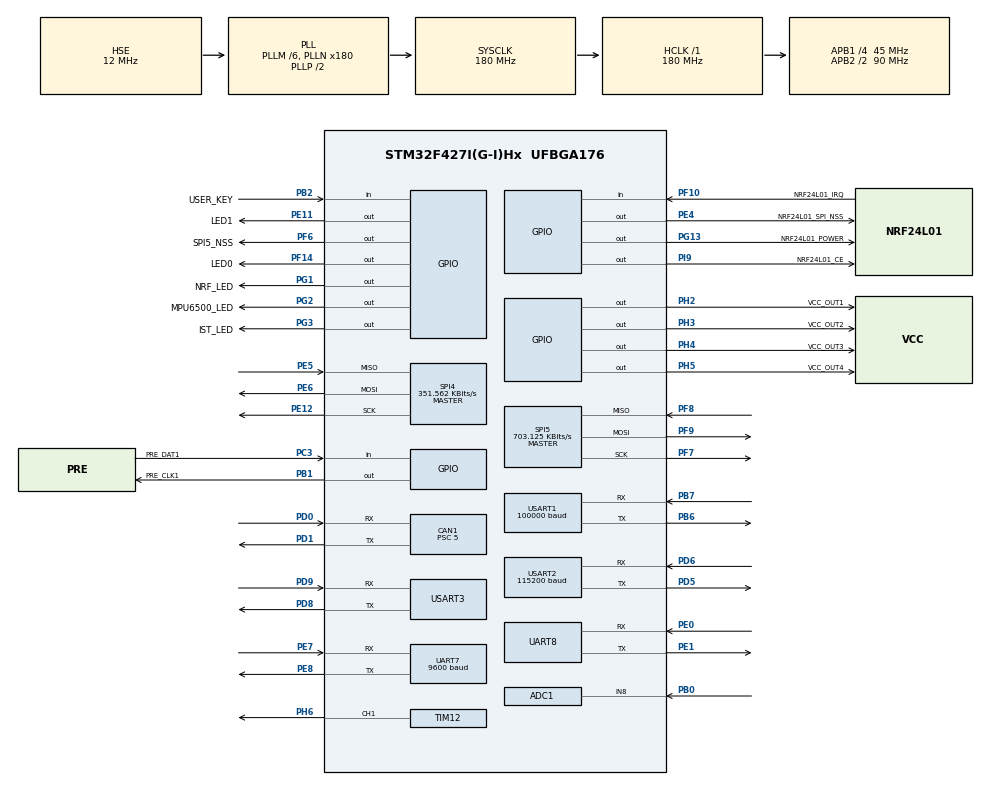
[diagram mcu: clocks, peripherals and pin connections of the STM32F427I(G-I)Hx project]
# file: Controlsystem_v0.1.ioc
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ADC1.Channel-0\#ChannelRegularConversion=ADC_CHANNEL_8
ADC1.NbrOfConversionFlag=1
ADC1.Rank-0\#ChannelRegularConversion=1
ADC1.SamplingTime-0\#ChannelRegularConversion=ADC_SAMPLETIME_3CYCLES
ADC1.master=1
CAN1.ABOM=ENABLE
CAN1.AWUM=DISABLE
CAN1.BS1=CAN_BS1_3TQ
CAN1.BS2=CAN_BS2_5TQ
CAN1.CalculateBaudRate=1000000
CAN1.CalculateTimeBit=1000
CAN1.CalculateTimeQuantum=111.11111111111111
CAN1.NART=DISABLE
CAN1.Prescaler=5
Dma.Request0=USART1_RX
Dma.Request1=USART3_RX
Dma.Request2=USART3_TX
Dma.Request3=UART8_RX
Dma.Request4=UART8_TX
Dma.UART8_RX.3.Direction=DMA_PERIPH_TO_MEMORY
Dma.UART8_RX.3.FIFOMode=DMA_FIFOMODE_DISABLE
Dma.UART8_RX.3.Instance=DMA1_Stream6
Dma.UART8_RX.3.MemDataAlignment=DMA_MDATAALIGN_BYTE
Dma.UART8_RX.3.MemInc=DMA_MINC_ENABLE
Dma.UART8_RX.3.Mode=DMA_NORMAL
Dma.UART8_RX.3.PeriphDataAlignment=DMA_PDATAALIGN_BYTE
Dma.UART8_RX.3.PeriphInc=DMA_PINC_DISABLE
Dma.UART8_RX.3.Priority=DMA_PRIORITY_LOW
Dma.UART8_TX.4.Direction=DMA_MEMORY_TO_PERIPH
Dma.UART8_TX.4.FIFOMode=DMA_FIFOMODE_DISABLE
Dma.UART8_TX.4.Instance=DMA1_Stream0
Dma.UART8_TX.4.MemDataAlignment=DMA_MDATAALIGN_BYTE
Dma.UART8_TX.4.MemInc=DMA_MINC_ENABLE
Dma.UART8_TX.4.Mode=DMA_NORMAL
Dma.UART8_TX.4.PeriphDataAlignment=DMA_PDATAALIGN_BYTE
Dma.UART8_TX.4.PeriphInc=DMA_PINC_DISABLE
Dma.UART8_TX.4.Priority=DMA_PRIORITY_LOW
Dma.USART1_RX.0.Direction=DMA_PERIPH_TO_MEMORY
Dma.USART1_RX.0.FIFOMode=DMA_FIFOMODE_DISABLE
Dma.USART1_RX.0.Instance=DMA2_Stream2
Dma.USART1_RX.0.MemDataAlignment=DMA_MDATAALIGN_BYTE
Dma.USART1_RX.0.MemInc=DMA_MINC_ENABLE
Dma.USART1_RX.0.Mode=DMA_CIRCULAR
Dma.USART1_RX.0.PeriphDataAlignment=DMA_PDATAALIGN_BYTE
Dma.USART1_RX.0.PeriphInc=DMA_PINC_DISABLE
Dma.USART1_RX.0.Priority=DMA_PRIORITY_LOW
Dma.USART3_RX.1.Direction=DMA_PERIPH_TO_MEMORY
Dma.USART3_RX.1.FIFOMode=DMA_FIFOMODE_DISABLE
Dma.USART3_RX.1.Instance=DMA1_Stream1
Dma.USART3_RX.1.MemDataAlignment=DMA_MDATAALIGN_BYTE
Dma.USART3_RX.1.MemInc=DMA_MINC_ENABLE
Dma.USART3_RX.1.Mode=DMA_NORMAL
Dma.USART3_RX.1.PeriphDataAlignment=DMA_PDATAALIGN_BYTE
Dma.USART3_RX.1.PeriphInc=DMA_PINC_DISABLE
Dma.USART3_RX.1.Priority=DMA_PRIORITY_VERY_HIGH
Dma.USART3_TX.2.Direction=DMA_MEMORY_TO_PERIPH
Dma.USART3_TX.2.FIFOMode=DMA_FIFOMODE_DISABLE
Dma.USART3_TX.2.Instance=DMA1_Stream3
Dma.USART3_TX.2.MemDataAlignment=DMA_MDATAALIGN_BYTE
Dma.USART3_TX.2.MemInc=DMA_MINC_ENABLE
Dma.USART3_TX.2.Mode=DMA_NORMAL
Dma.USART3_TX.2.PeriphDataAlignment=DMA_PDATAALIGN_BYTE
Dma.USART3_TX.2.PeriphInc=DMA_PINC_DISABLE
Dma.USART3_TX.2.Priority=DMA_PRIORITY_HIGH
FREERTOS.INCLUDE_xTaskGetHandle=1
FREERTOS.Tasks01=defaultTask,-3,128,StartDefaultTask,Default,NULL,Dynamic,NULL,NULL;MotorTask,3,128,Motordrive_task,As weak,NULL,Dynamic,NULL,NULL;ARHSTask,2,512,arhs_task,As weak,NULL,Dynamic,NULL,NULL;GimbalTask,-2,256,gimbal_task,As weak,NULL,Dynamic,NULL,NULL;MeasureTask,1,128,measureTask,As weak,NULL,Dynamic,NULL,NULL;ComTask,0,256,comTask,As weak,NULL,Dynamic,NULL,NULL
FREERTOS.configENABLE_FPU=1
FREERTOS.configTOTAL_HEAP_SIZE=49152
FREERTOS.configUSE_APPLICATION_TASK_TAG=0
FREERTOS.configUSE_NEWLIB_REENTRANT=1
Mcu.Family=STM32F4
Mcu.Name=STM32F427I(G-I)Hx
Mcu.Package=UFBGA176
NVIC.CAN1_RX0_IRQn=true\:2\:0\:true\:false\:true\:false\:true\:true
NVIC.CAN1_TX_IRQn=true\:2\:0\:true\:false\:true\:false\:true\:true
NVIC.DMA1_Stream0_IRQn=true\:5\:0\:false\:false\:true\:true\:false\:true
NVIC.DMA1_Stream1_IRQn=true\:5\:0\:false\:false\:true\:true\:false\:true
NVIC.DMA1_Stream3_IRQn=true\:5\:0\:false\:false\:true\:true\:false\:true
NVIC.DMA1_Stream6_IRQn=true\:5\:0\:false\:false\:true\:true\:false\:true
NVIC.DMA2_Stream2_IRQn=true\:0\:0\:true\:false\:true\:false\:false\:true
NVIC.PriorityGroup=NVIC_PRIORITYGROUP_4
NVIC.TIM6_DAC_IRQn=true\:0\:0\:false\:false\:true\:false\:false\:true
NVIC.TimeBase=TIM6_DAC_IRQn
NVIC.TimeBaseIP=TIM6
NVIC.UART7_IRQn=true\:4\:0\:true\:false\:true\:false\:true\:true
NVIC.UART8_IRQn=true\:5\:0\:false\:false\:true\:true\:true\:true
NVIC.USART1_IRQn=true\:4\:0\:true\:false\:true\:false\:true\:true
NVIC.USART3_IRQn=true\:3\:0\:true\:false\:true\:false\:true\:true
PA13.Mode=Trace_Asynchronous_SW
PA13.Signal=SYS_JTMS-SWDIO
PA14.Mode=Trace_Asynchronous_SW
PA14.Signal=SYS_JTCK-SWCLK
PB0.Signal=ADCx_IN8
PB1.GPIO_Label=PRE_CLK1
PB1.GPIO_PuPd=GPIO_PULLUP
PB1.GPIO_Speed=GPIO_SPEED_FREQ_LOW
PB1.Signal=GPIO_Output
PB2/BOOT1.GPIO_Label=USER_KEY
PB2/BOOT1.GPIO_PuPd=GPIO_PULLUP
PB2/BOOT1.Signal=GPIO_Input
PB3.Mode=Trace_Asynchronous_SW
PB3.Signal=SYS_JTDO-SWO
PB6.Mode=Asynchronous
PB6.Signal=USART1_TX
PB7.Mode=Asynchronous
PB7.Signal=USART1_RX
PC14/OSC32_IN.Mode=LSE-External-Oscillator
PC14/OSC32_IN.Signal=RCC_OSC32_IN
PC15/OSC32_OUT.Mode=LSE-External-Oscillator
PC15/OSC32_OUT.Signal=RCC_OSC32_OUT
PC3.GPIO_Label=PRE_DAT1
PC3.GPIO_PuPd=GPIO_PULLUP
PC3.Signal=GPIO_Input
PD0.Mode=CAN_Activate
PD0.Signal=CAN1_RX
PD1.Mode=CAN_Activate
PD1.Signal=CAN1_TX
PD5.GPIO_PuPd=GPIO_NOPULL
PD5.Mode=Asynchronous
PD5.Signal=USART2_TX
PD6.Mode=Asynchronous
PD6.Signal=USART2_RX
PD8.Mode=Asynchronous
PD8.Signal=USART3_TX
PD9.Mode=Asynchronous
PD9.Signal=USART3_RX
PE0.Mode=Asynchronous
PE0.Signal=UART8_RX
PE1.Mode=Asynchronous
PE1.Signal=UART8_TX
PE11.GPIO_Label=LED1
PE11.GPIO_PuPd=GPIO_PULLUP
PE11.GPIO_Speed=GPIO_SPEED_FREQ_LOW
PE11.PinState=GPIO_PIN_RESET
PE11.Signal=GPIO_Output
PE12.GPIO_PuPd=GPIO_NOPULL
PE12.Mode=Full_Duplex_Master
PE12.Signal=SPI4_SCK
PE4.GPIO_Label=NRF24L01_SPI_NSS
PE4.GPIO_PuPd=GPIO_PULLUP
PE4.GPIO_Speed=GPIO_SPEED_FREQ_VERY_HIGH
PE4.PinState=GPIO_PIN_SET
PE4.Signal=GPIO_Output
PE5.GPIO_PuPd=GPIO_NOPULL
PE5.Mode=Full_Duplex_Master
PE5.Signal=SPI4_MISO
PE6.GPIO_PuPd=GPIO_NOPULL
PE6.Mode=Full_Duplex_Master
PE6.Signal=SPI4_MOSI
PE7.Mode=Asynchronous
PE7.Signal=UART7_RX
PE8.Mode=Asynchronous
PE8.Signal=UART7_TX
PF10.GPIO_Label=NRF24L01_IRQ
PF10.GPIO_PuPd=GPIO_NOPULL
PF10.Signal=GPIO_Input
PF14.GPIO_Label=LED0
PF14.GPIO_PuPd=GPIO_PULLUP
PF14.Signal=GPIO_Output
PF6.GPIO_Label=SPI5_NSS
PF6.GPIO_Speed=GPIO_SPEED_FREQ_MEDIUM
PF6.PinState=GPIO_PIN_SET
PF6.Signal=GPIO_Output
PF7.Mode=Full_Duplex_Master
PF7.Signal=SPI5_SCK
PF8.Mode=Full_Duplex_Master
PF8.Signal=SPI5_MISO
PF9.Mode=Full_Duplex_Master
PF9.Signal=SPI5_MOSI
PG1.GPIO_Label=NRF_LED
PG1.PinState=GPIO_PIN_SET
PG1.Signal=GPIO_Output
PG13.GPIO_Label=NRF24L01_POWER
PG13.Signal=GPIO_Output
PG2.GPIO_Label=MPU6500_LED
PG2.PinState=GPIO_PIN_RESET
PG2.Signal=GPIO_Output
PG3.GPIO_Label=IST_LED
PG3.PinState=GPIO_PIN_SET
PG3.Signal=GPIO_Output
PH0/OSC_IN.Mode=HSE-External-Oscillator
PH0/OSC_IN.Signal=RCC_OSC_IN
PH1/OSC_OUT.Mode=HSE-External-Oscillator
PH1/OSC_OUT.Signal=RCC_OSC_OUT
PH2.GPIO_Label=VCC_OUT1
PH2.Signal=GPIO_Output
PH3.GPIO_Label=VCC_OUT2
PH3.Signal=GPIO_Output
PH4.GPIO_Label=VCC_OUT3
PH4.Signal=GPIO_Output
PH5.GPIO_Label=VCC_OUT4
PH5.Signal=GPIO_Output
PH6.Signal=S_TIM12_CH1
PI9.GPIO_Label=NRF24L01_CE
PI9.GPIO_PuPd=GPIO_PULLUP
PI9.GPIO_Speed=GPIO_SPEED_FREQ_VERY_HIGH
PI9.Signal=GPIO_Output
ProjectManager.HeapSize=0x200
ProjectManager.StackSize=0x400
ProjectManager.TargetToolchain=STM32CubeIDE
RCC.48MHZClocksFreq_Value=90000000
RCC.AHBFreq_Value=180000000
RCC.APB1CLKDivider=RCC_HCLK_DIV4
RCC.APB1Freq_Value=45000000
RCC.APB1TimFreq_Value=90000000
RCC.APB2CLKDivider=RCC_HCLK_DIV2
RCC.APB2Freq_Value=90000000
RCC.APB2TimFreq_Value=180000000
RCC.CortexFreq_Value=180000000
RCC.HCLKFreq_Value=180000000
RCC.HSE_VALUE=12000000
RCC.HSI_VALUE=16000000
RCC.PLLM=6
RCC.PLLN=180
RCC.PLLSourceVirtual=RCC_PLLSOURCE_HSE
RCC.RCC_TIM_PRescaler_Selection=RCC_TIMPRES_DESACTIVATED
RCC.SYSCLKFreq_VALUE=180000000
RCC.SYSCLKSource=RCC_SYSCLKSOURCE_PLLCLK
RCC.VCOOutputFreq_Value=360000000
SH.ADCx_IN8.0=ADC1_IN8,IN8
SH.S_TIM12_CH1.0=TIM12_CH1,PWM Generation1 CH1
SPI4.BaudRatePrescaler=SPI_BAUDRATEPRESCALER_256
SPI4.CLKPhase=SPI_PHASE_1EDGE
SPI4.CLKPolarity=SPI_POLARITY_LOW
SPI4.CalculateBaudRate=351.562 KBits/s
SPI4.Direction=SPI_DIRECTION_2LINES
SPI4.Mode=SPI_MODE_MASTER
SPI4.VirtualType=VM_MASTER
SPI5.BaudRatePrescaler=SPI_BAUDRATEPRESCALER_128
SPI5.CLKPhase=SPI_PHASE_2EDGE
SPI5.CLKPolarity=SPI_POLARITY_HIGH
SPI5.CalculateBaudRate=703.125 KBits/s
SPI5.Direction=SPI_DIRECTION_2LINES
SPI5.Mode=SPI_MODE_MASTER
SPI5.VirtualType=VM_MASTER
TIM12.Channel-PWM\ Generation1\ CH1=TIM_CHANNEL_1
TIM12.Period=22499
TIM14.AutoReloadPreload=TIM_AUTORELOAD_PRELOAD_DISABLE
TIM14.ClockDivision=TIM_CLOCKDIVISION_DIV2
TIM14.Period=65535
TIM14.Prescaler=45
TIM3.Period=4999
UART7.BaudRate=9600
UART7.VirtualMode=Asynchronous
UART8.VirtualMode=Asynchronous
USART1.BaudRate=100000
USART1.Parity=PARITY_EVEN
USART1.VirtualMode=VM_ASYNC
USART2.BaudRate=115200
USART2.VirtualMode=VM_ASYNC
USART3.VirtualMode=VM_ASYNC
VP_FREERTOS_VS_CMSIS_V1.Mode=CMSIS_V1
VP_SYS_VS_tim6.Mode=TIM6
VP_TIM12_VS_ClockSourceINT.Mode=Internal
VP_TIM14_VS_ClockSourceINT.Mode=Enable_Timer
VP_TIM3_VS_ClockSourceINT.Mode=Internal
board=custom

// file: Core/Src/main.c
/* USER CODE BEGIN Header */
/**
  ******************************************************************************
  * @file           : main.c
  * @brief          : Main program body
  ******************************************************************************
  * @attention
  *
  * <h2><center>&copy; Copyright (c) 2020 STMicroelectronics.
  * All rights reserved.</center></h2>
  *
  * This software component is licensed by ST under BSD 3-Clause license,
  * the "License"; You may not use this file except in compliance with the
  * License. You may obtain a copy of the License at:
  *                        opensource.org/licenses/BSD-3-Clause
  *
  ******************************************************************************
  */
/* USER CODE END Header */
#include "main.h"
#include "FreeRTOS.h"
#include "cmsis_os.h"
#include "adc.h"
#include "can.h"
#include "dma.h"
#include "spi.h"
#include "tim.h"
#include "usart.h"
#include "gpio.h"

/* USER CODE BEGIN Includes */

//extern UART_HandleTypeDef huart7;

/* USER CODE END Includes */

/* USER CODE BEGIN PTD */
//extern CAN_HandleTypeDef hcan1;
extern TIM_HandleTypeDef htim12;
/* USER CODE END PTD */

void SystemClock_Config(void);
void MX_FREERTOS_Init(void);

int main(void)
{

  /* MCU Configuration--------------------------------------------------------*/

  /* Reset of all peripherals, Initializes the Flash interface and the Systick. */
  HAL_Init();

  /* Configure the system clock */
  SystemClock_Config();

  /* Initialize all configured peripherals */
  MX_GPIO_Init();
  MX_DMA_Init();
  MX_USART2_UART_Init();
  MX_USART1_UART_Init();
  MX_CAN1_Init();
  MX_SPI5_Init();
  MX_TIM3_Init();
  MX_UART7_Init();
  MX_USART3_UART_Init();
  MX_SPI4_Init();
  MX_ADC1_Init();
  MX_TIM14_Init();
  MX_TIM12_Init();
  MX_UART8_Init();
  /* USER CODE BEGIN 2 */
  //__HAL_UART_ENABLE_IT(&huart7, UART_IT_RXNE);
  HAL_TIM_Base_Start(&htim12);		//开启蜂鸣器定时器
  HAL_TIM_PWM_Start(&htim12, TIM_CHANNEL_1);	//开启蜂鸣器PWM波定时器

  /* USER CODE END 2 */

  /* Call init function for freertos objects (in freertos.c) */
  MX_FREERTOS_Init();
  /* Start scheduler */
  osKernelStart();

  /* We should never get here as control is now taken by the scheduler */
  /* Infinite loop */
  while (1)
  {

  }
}

void SystemClock_Config(void)
{
  RCC_OscInitTypeDef RCC_OscInitStruct = {0};
  RCC_ClkInitTypeDef RCC_ClkInitStruct = {0};

  /** Configure the main internal regulator output voltage
  */
  __HAL_RCC_PWR_CLK_ENABLE();
  __HAL_PWR_VOLTAGESCALING_CONFIG(PWR_REGULATOR_VOLTAGE_SCALE1);
  /** Initializes the RCC Oscillators according to the specified parameters
  * in the RCC_OscInitTypeDef structure.
  */
  RCC_OscInitStruct.OscillatorType = RCC_OSCILLATORTYPE_HSE;
  RCC_OscInitStruct.HSEState = RCC_HSE_ON;
  RCC_OscInitStruct.PLL.PLLState = RCC_PLL_ON;
  RCC_OscInitStruct.PLL.PLLSource = RCC_PLLSOURCE_HSE;
  RCC_OscInitStruct.PLL.PLLM = 6;
  RCC_OscInitStruct.PLL.PLLN = 180;
  RCC_OscInitStruct.PLL.PLLP = RCC_PLLP_DIV2;
  RCC_OscInitStruct.PLL.PLLQ = 4;
  if (HAL_RCC_OscConfig(&RCC_OscInitStruct) != HAL_OK)
  {
    Error_Handler();
  }
  /** Activate the Over-Drive mode
  */
  if (HAL_PWREx_EnableOverDrive() != HAL_OK)
  {
    Error_Handler();
  }
  /** Initializes the CPU, AHB and APB buses clocks
  */
  RCC_ClkInitStruct.ClockType = RCC_CLOCKTYPE_HCLK|RCC_CLOCKTYPE_SYSCLK
                              |RCC_CLOCKTYPE_PCLK1|RCC_CLOCKTYPE_PCLK2;
  RCC_ClkInitStruct.SYSCLKSource = RCC_SYSCLKSOURCE_PLLCLK;
  RCC_ClkInitStruct.AHBCLKDivider = RCC_SYSCLK_DIV1;
  RCC_ClkInitStruct.APB1CLKDivider = RCC_HCLK_DIV4;
  RCC_ClkInitStruct.APB2CLKDivider = RCC_HCLK_DIV2;

  if (HAL_RCC_ClockConfig(&RCC_ClkInitStruct, FLASH_LATENCY_5) != HAL_OK)
  {
    Error_Handler();
  }
}

void HAL_TIM_PeriodElapsedCallback(TIM_HandleTypeDef *htim)
{
  if (htim->Instance == TIM6) {
    HAL_IncTick();
  }
}

void Error_Handler(void)
{
  /* USER CODE BEGIN Error_Handler_Debug */
  /* User can add his own implementation to report the HAL error return state */
	//printf("init is error\n");
  /* USER CODE END Error_Handler_Debug */
}

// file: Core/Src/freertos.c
/* USER CODE BEGIN Header */
/**
  ******************************************************************************
  * File Name          : freertos.c
  * Description        : Code for freertos applications
  ******************************************************************************
  * @attention
  *
  * <h2><center>&copy; Copyright (c) 2020 STMicroelectronics.
  * All rights reserved.</center></h2>
  *
  * This software component is licensed by ST under Ultimate Liberty license
  * SLA0044, the "License"; You may not use this file except in compliance with
  * the License. You may obtain a copy of the License at:
  *                             www.st.com/SLA0044
  *
  ******************************************************************************
  */
/* USER CODE END Header */

#include "FreeRTOS.h"
#include "task.h"
#include "main.h"
#include "cmsis_os.h"

/* USER CODE BEGIN Includes */
#include "gpio.h"
#include "stm32f4xx_it.h"
#include "usart.h"
#include "can.h"

/* USER CODE END Includes */

/* USER CODE BEGIN Variables */
//extern uint8_t rcbuffer[18];
//extern RC_Ctl_t RC_CtrlData;
//extern CAN_HandleTypeDef hcan1;
//extern UART_HandleTypeDef huart2;
//extern CAN_HandleTypeDef hcan2;

//extern UART_HandleTypeDef huart1;
/* USER CODE END Variables */
osThreadId defaultTaskHandle;
osThreadId MotorTaskHandle;
osThreadId ARHSTaskHandle;
osThreadId GimbalTaskHandle;
osThreadId MeasureTaskHandle;
osThreadId ComTaskHandle;

void StartDefaultTask(void const * argument);
void Motordrive_task(void const * argument);
void arhs_task(void const * argument);
void gimbal_task(void const * argument);
void measureTask(void const * argument);
void comTask(void const * argument);

void MX_FREERTOS_Init(void); /* (MISRA C 2004 rule 8.1) */

/* GetIdleTaskMemory prototype (linked to static allocation support) */
void vApplicationGetIdleTaskMemory( StaticTask_t **ppxIdleTaskTCBBuffer, StackType_t **ppxIdleTaskStackBuffer, uint32_t *pulIdleTaskStackSize );

/* USER CODE BEGIN GET_IDLE_TASK_MEMORY */
static StaticTask_t xIdleTaskTCBBuffer;
static StackType_t xIdleStack[configMINIMAL_STACK_SIZE];

void vApplicationGetIdleTaskMemory( StaticTask_t **ppxIdleTaskTCBBuffer, StackType_t **ppxIdleTaskStackBuffer, uint32_t *pulIdleTaskStackSize )
{
  *ppxIdleTaskTCBBuffer = &xIdleTaskTCBBuffer;
  *ppxIdleTaskStackBuffer = &xIdleStack[0];
  *pulIdleTaskStackSize = configMINIMAL_STACK_SIZE;
  /* place for user code */
}
/* USER CODE END GET_IDLE_TASK_MEMORY */

void MX_FREERTOS_Init(void) {

  /* Create the thread(s) */
  /* definition and creation of defaultTask */
  osThreadDef(defaultTask, StartDefaultTask, osPriorityIdle, 0, 128);
  defaultTaskHandle = osThreadCreate(osThread(defaultTask), NULL);

  /* definition and creation of MotorTask */
  osThreadDef(MotorTask, Motordrive_task, osPriorityRealtime, 0, 128);
  MotorTaskHandle = osThreadCreate(osThread(MotorTask), NULL);

  /* definition and creation of ARHSTask */
  osThreadDef(ARHSTask, arhs_task, osPriorityHigh, 0, 512);
  ARHSTaskHandle = osThreadCreate(osThread(ARHSTask), NULL);

  /* definition and creation of GimbalTask */
  osThreadDef(GimbalTask, gimbal_task, osPriorityLow, 0, 256);
  GimbalTaskHandle = osThreadCreate(osThread(GimbalTask), NULL);

  /* definition and creation of MeasureTask */
  osThreadDef(MeasureTask, measureTask, osPriorityAboveNormal, 0, 128);
  MeasureTaskHandle = osThreadCreate(osThread(MeasureTask), NULL);

  /* definition and creation of ComTask */
  osThreadDef(ComTask, comTask, osPriorityNormal, 0, 256);
  ComTaskHandle = osThreadCreate(osThread(ComTask), NULL);

}

void StartDefaultTask(void const * argument)
{
  for(;;)
  {
    osDelay(1);
  }
}

__weak void Motordrive_task(void const * argument)
{
  for(;;)
  {
    osDelay(1);
  }
}

__weak void arhs_task(void const * argument)
{
  for(;;)
  {
    osDelay(1);
  }
}

__weak void gimbal_task(void const * argument)
{
  for(;;)
  {
    osDelay(1);
  }
}

__weak void measureTask(void const * argument)
{
  for(;;)
  {
    osDelay(1);
  }
}

__weak void comTask(void const * argument)
{
  for(;;)
  {
    osDelay(1);
  }
}
